# NUC1263AE register map
File version: 1.0
Registers are 32-bit, read-write, reset 0x0 unless marked. A register's access mark holds for its fields unless they carry their own. Offsets are from the block's base; [hi:lo] are bit positions; {n}, {i} and the like mark numbered series; 'fields as' and 'values as' point back to an identical list.

## I3CS0 — I3CS Register Map
Base 0x40070000
Same registers: I3CS1 0x40170000
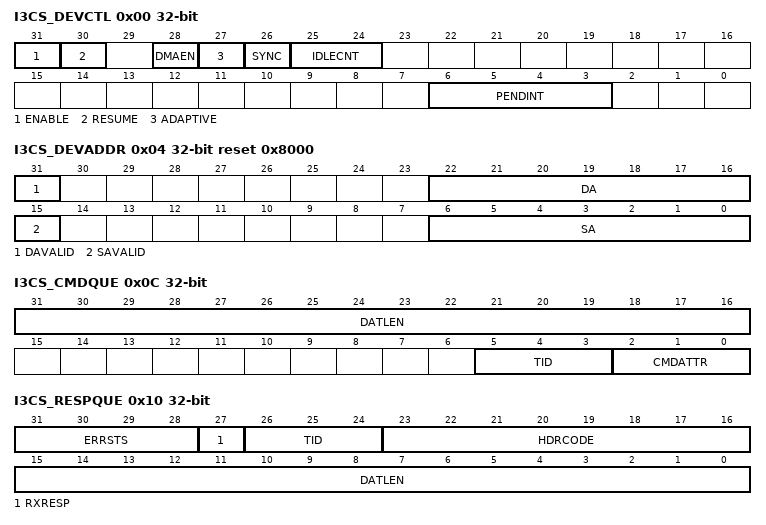
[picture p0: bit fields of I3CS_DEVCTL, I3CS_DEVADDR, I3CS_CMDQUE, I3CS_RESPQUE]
0x00 I3CS_DEVCTL — I3CS Device Control Register
  [31] ENABLE — Controls whether I3CS is enabled. This bit is used to disable or enable the I3CS cntroller. Note: User can read I3C_DEVCTL[26] SYNC bit to monitor enable/disable I3C is completion ot not.
    0=I3CS controller Disabled; 1=I3CS controller Enabled
  [30] RESUME — I3CS Resume Bit. This bit is used to resume the controller after it goes to the halt state. Note 1: This bit is cleared by writing 1 to it. Note 2: In the Slave mode of operation, the controller goes to the halt state due to following conditions: Any type of error in the transfer. MRL Register (I3CS_SLVMXLEN[31:16]) updated by the master through SETMRL CCC. Note 3: After the controller goes to the halt state, the application has to take necessary action to handle the error condition and then write 1'b1 to this bit to resume the controller. This bit is auto-cleared once the controller is ready to accept new transfers.RESUME cannot be auto cleared until GETSTATS CCC is received if Slave has Protocol Error.
    0=RESUME operation is completion; 1=RESUME operation is in progress
  [28] DMAEN — DMA Handshake Interface Enable
    0=The DMA handshake control has no significance; 1=Enables the DMA handshake control to interact with external DMA
  [27] ADAPTIVE — Adaptive Mode. Setting of this bit is NOT required to put the controller in Adaptive Mode. It is only used to enable some features of the Slave controller to adapt to Adaptive I2C/I3C mode of operation. This bit is cleared automatically if the controller determines the mode as I3C. (Effect on Hot- Join). If this bit is programmed to 1'b1, the controller initiates a Hot-Join request only after it has switched to I3C mode of operation. If this bit is not set, the controller initiates a Hot- Join without determining the bus mode assuming itself to be on i3c bus. This bit should be set only if the Slave application does not know to which bus the device is connected to.
    0=Adptive mode is Disabled; 1=Adptive mode is Enabled
  [26] SYNC ro — Enable I3C Controller SYNC Flag (Read Only)
    0=Enables the I3C controller is completed; 1=Enables the I3C controller is ongoing
  [25:24] IDLECNT — Idle Count Multiplier. After power-on reset, the Slave controller is enabled only after it sees both SDA and SCL lines idle for a specified time. This idle time is calculated by multiplying IDLECNT with Bus Avaliable Time.
    0=1 Idle Count; 1=2 Idle Counts; 2=4 Idle Counts; 3=8 Idle Counts
  [6:3] PENDINT — Pending Interrupt Status. This field is used for setting the interrupt number and is also reflected in I3CS_CCCDEVS[3:0] PENDINT.
0x04 I3CS_DEVADDR reset 0x8000 — I3CS Device Address Register
  [31] DAVALID — Dynamic Address Valid. In I3C Slave mode, the Controller sets this bit to 1 when Main Master assigns the Dynamic address during ENTDAA or SETDASA mechanism. Note: This bit can be auto cleared to 0 if RSTDAA CCC is received.
    0=Dynamic Address is invalid; 1=Dynamic Address is valid
  [22:16] DA ro — Device Dynamic Address (Read Only). This field is used to indicate the device Dynamic Address after slave completes the dynamic address assignment operation by ENTDAA, SETDASA or SETNEDA CCC.
  [15] SAVALID — Static Address Valid. This bit reflects whether the I2C static address is valid in I2C slave mode.
    0=Static Address is invalid; 1=Static Address is valid
  [6:0] SA — Device Static Address. The I2C static address is used to respond to SETDASA CCC Command to get the Dynamic Address or performs Legacy I2C Read/Write operation.
0x0C I3CS_CMDQUE wo — I3CS Command Queue Port Register
  [31:16] DATLEN — Data Length. This field is used to indicate the data length in bytes of the master read transfer.
  [5:3] TID — Transmit Transaction ID. This field is used as the identification tag for the command.
  [2:0] CMDATTR — Command Attribute. Defines the command attribute and its field format.
    0=Transmit Command without IBI
0x10 I3CS_RESPQUE ro — I3CS Response Queue Port Register
  [31:28] ERRSTS — Error Status
    0=No Error; 1=CRC error (master write in DDR mode); 2=Parity error (master write in both DDR and SDR mode); 3=Frame error (HDR mode master write); 6=Underflow/Overflow error; 10=Master early termination
  [27] RXRESP — Transaction Type. This field is used to identify the type of transaction.
    0=Transmit Response occurred; 1=Receive Response occurred
  [26:24] TID — Transmit Transaction ID. This field is used as the identification tag for the transmit command.
  [23:16] HDRCODE — HDR Command Code
    0=SDR Transfer
  [15:0] DATLEN — Data Length. Data Length in bytes of Master Write Transfer or the Remaining Length of Master Read Transfer (Master termination or Slave underrun).
0x14 I3CS_TXRXDAT — I3CS Transmit and Receive Data Port Register
  [31:0] DAT — Transmit and Receive Data Port. Transmit (Write) Operation: The Transmit Data port is mapped to the Tx-Data Buffer. The transmit data should always be packed as 4-byte aligned data words and written to the Transmit Data Port register. If the Command length is not aligned to 4-bytes, then the additional bytes are ignored. Receive (Read) Operation: The Receive Data port is mapped to the Rx-Data Buffer. The Receive data is always packed in 4-byte aligned data words and stored in the Rx-Data Buffer. If the command length is not aligned to the 4-bytes, then the additional data bytes have to be ignored.
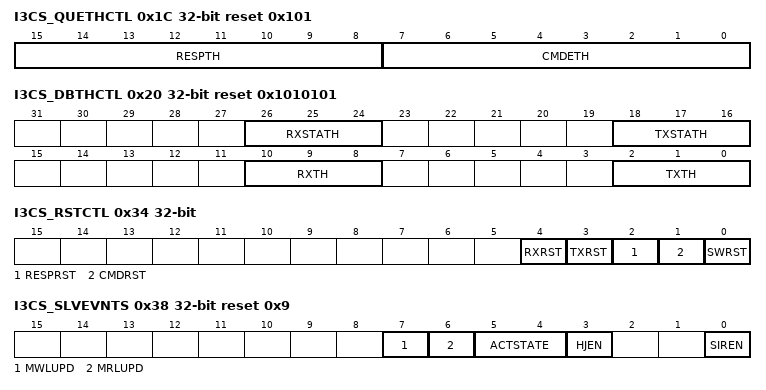
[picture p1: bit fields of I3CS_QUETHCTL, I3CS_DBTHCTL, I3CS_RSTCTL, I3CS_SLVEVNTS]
0x1C I3CS_QUETHCTL reset 0x101 — I3CS Queue Threshold Control Register
  [15:8] RESPTH — Response Buffer Threshold Value. Controls the number of entries (or greater) in the ResponseQueue that trigger the Response Queue Ready interrupt (RESPRDY). The valid range is 0 to 1. The software programs only valid values. A value of 0 sets the threshold for 1 entry, and a value of N sets the threshold for N+1 entries.
  [7:0] CMDETH — Command Buffer Empty Threshold Value. Controls the number of empty locations (or greater) in the Command Queue that trigger the Command Queue Ready interrupt (CMDRDY). The valid range is 0 to 3. The software programs only valid values. Value of N ranging from 1 to 3 sets the threshold to N empty locations and a value of 0 sets the threshold to indicate that the queue is completely empty.
0x20 I3CS_DBTHCTL reset 0x1010101 — I3CS Data Buffer Threshold Control Register
  [all] fields
    0=1; 1=4; 2=8; 3=16
  [26:24] RXSTATH — Receive Start Threshold Value. In the slave mode of operation the slave controller ACK's a write request from Master only if threshold number of empty locations(or more) are available in its receive buffer. The supported values for RXSTATH are:
  [18:16] TXSTATH — Transfer Start Threshold Value. In slave mode of operation the slave controller ACK's a read request from Master only if either one of the following conditions are met: 1. Data length (as specified in the command) number of locations are filled in the Transmit FIFO. 2. Threshold number of entries (or more) are available in the Transmit FIFO. The supported values for RXSTATH are:
  [10:8] RXTH — Receive Buffer Threshold Value. The supported values for RXTH are
  [2:0] TXTH — Transmit Buffer Threshold Value. The supported values for TXTH are
0x34 I3CS_RSTCTL — I3CS Reset Control Register
  [4] RXRST — Receive Buffer Software Reset. Write 1'b1 to this bit to exercise Receive Buffer reset. This bit is cleared automatically once the Receive buffer reset is completed.
  [3] TXRST — Transmit Buffer Software Reset. Write 1'b1 to this bit to exercise Transmit Buffer reset. This bit is cleared automatically once the Transmit Buffer reset is completed.
  [2] RESPRST — Response Queue Software Reset. Write 1'b1 to this bit to exercise Response Queue reset. This bit is cleared automatically once the Response Queue reset is completed.
  [1] CMDRST — Command Queue Software Reset. Write 1'b1 to this bit to exercise Command Queue reset. This bit is cleared automatically once the Command Queue reset is completed.
  [0] SWRST — Core Software Reset. Write 1'b1 to this bit to exercise software reset. This resets all Buffers - Receive, Transmit and Queues - Command, and Response. This bit is cleared automatically once the core reset is completed.
0x38 I3CS_SLVEVNTS reset 0x9 — I3CS Slave Event Status Register
  [7] MWLUPD — MWL Updated Status. This bit indicates a SETMWL CCC is received by the slave. The updated MWL value can be read from I3CS_SLVMXLEN register. Note: This bit is cleared by writing 1 to it.
  [6] MRLUPD — MRL Updated Status. This bit indicates a SETMRL CCC is received by the slave. The updated MRL value can be read from I3CS_SLVMXLEN register. Note: This bit is cleared by writing 1 to it.
  [5:4] ACTSTATE ro — Activity State Status (Read Only). This bit reflects the Activity State of slave set by the Master. ENTAS0 - 00. ENTAS1 - 01. ENTAS2 - 10. ENTAS3 - 11
  [3] HJEN ro — Hot-Join Interrupt Enable Bit (Read Only). This bit reflects whether the Hot-Join Request Interrupts are allowed on the I3C bus or not. The Slave application can choose to Disable HJ Capability of the SLave Controller (if selected) by setting this field to 0 before 'Enabling' the Controller. When done so, the Slave does not initiate Hot Join and takes part in Address Assignment without initiating Hot Join. If this field is NOT set to 0 by slave application, it can be set or cleared by the I3C Master through ENEC or DISEC CCCs. Once Disabled by software, CCCs do not have any effect on this field.
  [0] SIREN ro — Slave Interrupt Request Enable Bit (Read Only). In Slave mode of operation, this bit reflects whether the controller can initiate the SIR on the I3C bus or not. Usually, this bit is set or cleared by the I3C Master through ENEC or DISEC CCC.
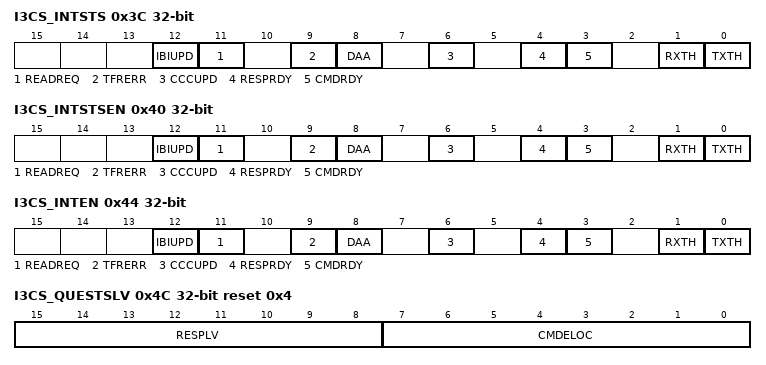
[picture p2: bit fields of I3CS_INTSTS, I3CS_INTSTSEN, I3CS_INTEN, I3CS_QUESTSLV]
0x3C I3CS_INTSTS — I3CS Interrupt Status Register
  [12] IBIUPD — IBI Status Updated. It indicates that the IBI request initiated through SIR request register is addressed and status is updated. Note: This bit is cleared by writing 1 to it.
  [11] READREQ — Read Request Received. Read Request received from the current master when CMDQ is empty. Note: This bit is cleared by writing 1 to it.
  [9] TFRERR — Transfer Error Status. This interrupt is generated if any error occurs during transfer. The error type is specified in the error status field of resopnse queue. Note: This bit is cleared by writing 1 to it.
  [8] DAA — Dynamic Address Assigned Status. This interrupt is generated if the device's Dynamic Address is assigned through SETDASA or ENTDAA CCC. Note: This bit is cleared by writing 1 to it.
  [6] CCCUPD — CCC Table Updated Status. This interrupt is generated if any of the CCC registers are updated by I3C Master through CCC commands. Note: This bit is cleared by writing 1 to it.
  [4] RESPRDY ro — Response Queue Ready Status (Read Only). This interrupt is generated when number of entries in response queue is greater than or equal to threshold valuespecified by RESPTH field in QUETHCTL register. This interrupt is cleared automatically when number of entries in response buffer is less than threshold value specified.
  [3] CMDRDY ro — Command Queue Ready Status (Read Only). This interrupt is generated when number of empty locations in command queue is greater than or equal to threshold value specified by CMDETH field in QUETHCTL register. This interrupt is cleared automatically when number of empty locations in command buffer is less than threshold value specified.
  [1] RXTH ro — Receive Buffer Threshold Status (Read Only). This interrupt is generated when number of entries in receive buffer is greater than or equal to threshold value specified by RXTH field in DBTHCTL register. This interrupt is cleared automatically when number of entries in receive buffer is less than threshold value specified.
  [0] TXTH ro — Transmit Buffer Threshold Status (Read Only). This interrupt is generated when the number of empty locations in transmit buffer is greater than or equal to threshold value specified by TXTH field in DBTHCTL register. This interrupt is cleared automatically when number of empty locations in transmit buffer is less than threshold value specified.
0x40 I3CS_INTSTSEN — I3CS Interrupt Status Enable Register
  [12] IBIUPD — IBI Updated Status Enable Bit
    0=IBI interrupt status Disabled; 1=IBI interrupt status Enabled
  [11] READREQ — Read Request Received Status Enable
    0=Read request received interrupt status Disabled; 1=Read request received interrupt status Enabled
  [9] TFRERR — Transfer Error Status Enable
    0=Transfer error interrupt status Disabled; 1=Transfer error interrupt status Enabled
  [8] DAA — Dynamic Address Assigned Status Enable
    0=DAA interrupt status Disabled; 1=DAA interrupt status Enabled
  [6] CCCUPD — CCC Table Updated Status Enable Bit
    0=CCC updated interrupt status Disabled; 1=CCC updated interrupt status Enabled
  [4] RESPRDY — Response Queue Ready Status Enable
    0=Response queue ready interrupt status Disabled; 1=Response queue ready interrupt status Enabled
  [3] CMDRDY — Command Queue Ready Status Enable
    0=Command queue ready interrupt status Disabled; 1=Command queue ready interrupt status Enabled
  [1] RXTH — Receive Buffer Threshold Status Enable
    0=RX buffer threshold interrupt status Disabled; 1=RX buffer threshold interrupt status Enabled
  [0] TXTH — Transmit Buffer Threshold Status Enable
    0=TX buffer threshold interrupt status Disabled; 1=TX buffer threshold interrupt status Enabled
0x44 I3CS_INTEN — I3CS Interrupt Signal Enable Register
  [12] IBIUPD — IBI Updated Signal Enable
    0=IBI interrupt Disabled; 1=IBI interrupt Enabled
  [11] READREQ — Read Request Received Signal Enable
    0=Read request received interrupt Disabled; 1=Read request received interrupt Enabled
  [9] TFRERR — Transfer Error Signal Enable
    0=Transfer error interrupt Disabled; 1=Transfer error interrupt Enabled
  [8] DAA — Dynamic Address Assigned Signal Enable
    0=DAA interrupt Disabled; 1=DAA interrupt Enabled
  [6] CCCUPD — CCC Table Updated Signal Enable
    values as I3CS_INTSTSEN.CCCUPD
  [4] RESPRDY — Response Queue Ready Signal Enable
    0=Response queue ready interrupt Disabled; 1=Response queue ready interrupt Enabled
  [3] CMDRDY — Command Queue Ready Signal Enable
    0=Command queue ready interrupt Disabled; 1=Command queue ready interrupt Enabled
  [1] RXTH — Receive Buffer Threshold Signal Enable
    0=RX buffer threshold interrupt Disabled; 1=RX buffer threshold interrupt Enabled
  [0] TXTH — Transmit Buffer Threshold Signal Enable
    0=TX buffer threshold interrupt Disabled; 1=TX buffer threshold interrupt Enabled
0x4C I3CS_QUESTSLV ro reset 0x4 — I3CS Queue Status Level Register
  [15:8] RESPLV — Response Buffer Level Value. Contains the number of valid data entries in the response Buffer.
  [7:0] CMDELOC — Command Queue Empty Locations. Contains the number of empty locations in the command Buffer.
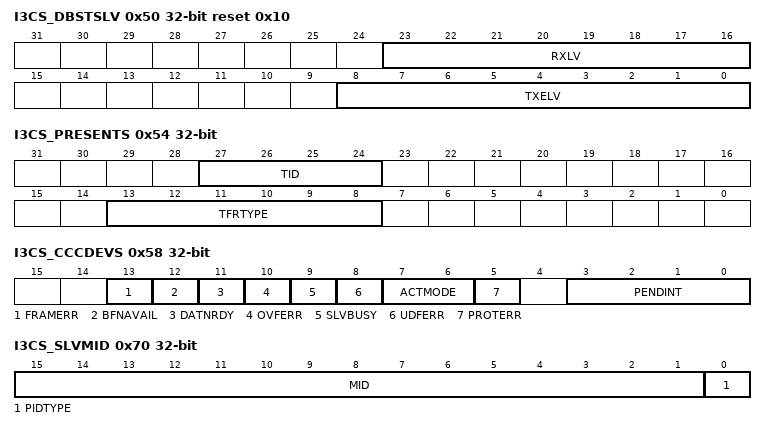
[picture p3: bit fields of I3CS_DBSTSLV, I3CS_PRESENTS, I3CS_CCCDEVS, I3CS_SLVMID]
0x50 I3CS_DBSTSLV ro reset 0x10 — I3CS Data Buffer Status Level Register
  [23:16] RXLV — Receive Buffer Level Value. Contains the number of valid data entries in the receive Buffer.
  [8:0] TXELV — Transmit Buffer Empty Level Value. Contains the number of empty locations in the transmit Buffer.
0x54 I3CS_PRESENTS ro — I3CS Present State Register
  [27:24] TID — Transmit Transaction ID. This field reflects the Transaction ID of the current executing command.
  [13:8] TFRTYPE — Transfer Type Status in Slave Mode
    0=IDLE (Controller is in Idle state); 1=Hot-Join transfer state; 2=IBI transfer state; 3=Master write transfer ongoing; 4=Read data prefetch state; 5=Master read transfer ongoing; 6=Slave controller in Halt State waiting for resume from application
0x58 I3CS_CCCDEVS ro — I3CS Device Operating Status Register
  [13] FRAMERR — Frame Error. This bit is set when private write request from Master has frame error in HDR-DDR mode. This is cleared only after Master reads the device status through GETSTATUS CCC.
    0=Frame error event did not occur; 1=Frame error event occurred
  [12] BFNAVAIL — Buffer Not Available. This bit is set when private write request from Master is NACKED because of RX buffer not having RXTH number of empty locations or Response buffer is full. In SDR mode of operation this is cleared when the Master issues GETSTATUS CCC or upon space becoming available in the buffer and the successful completion of the next write transfer. In HDR mode of operation it is cleared only when Master issues GETSTATUS CCC.
    0=Buffer not available event did not occur; 1=Buffer not available event occurred
  [11] DATNRDY — Data Not Ready. This bit is set when private read request from Master is NACKED because of any of the following conditions: Command FIFO Empty. Transmit FIFO threshold is not met. Response FIFO Full. This is cleared when the Master issues GETSTATUS CCC or upon successful completion of the subsequent read transfer.
    0=Data not ready event did not occur; 1=Data not ready event occurred
  [10] OVFERR — Overflow Error. This bit is set while overflow error condition detected during master write transfer. This is cleared only after master reads the Device Status through GETSTATUS CCC.
    0=Overflow error event did not occur; 1=Overflow error event occurred
  [9] SLVBUSY — Slave Busy. This bit is set if any change is made by the current master in to MRL register or occurance of any error. It is cleared after slave application resumes the slave operation by writing 1'b1 in RESUME field of I3CS_DEVCTL.
    0=Slave controller is not at busy state; 1=Slave controller is at busy state
  [8] UDFERR — Underflow Error. This bit is set if slave controller terminates a read transfer because of unavailability of data in the transmit buffer. This is cleared only after master reads the Device Status through GETSTATUS CCC.
    0=Underflow error event did not occur; 1=Underflow error event occurred
  [7:6] ACTMODE — Activity Mode. This field indicates current Activity Mode is fixed at 0 in NUC1263.
  [5] PROTERR — Protocol Error. This bit is set when the slave controller encouters a Parity/CRC error during write data transfer.
    0=Protocol error event did not occur; 1=Protocol error event occurred
  [3:0] PENDINT — Pending Interrupt. This field reflects the value in I3CS_DEVCTL[6:3].
0x70 I3CS_SLVMID — I3CS MIPI Manufacturer ID Register
  [15:1] MID — Specifies the MIPI Manufacturer ID. The value of this field is indicating the MIPI Manufacturer ID, PID[47:33].
  [0] PIDTYPE — Specifies the Provisional ID Type Selector. The value of this field is indicating the Provisional ID Type, PID[32].
    0=Vendor Fixed Value; 1=Random Value
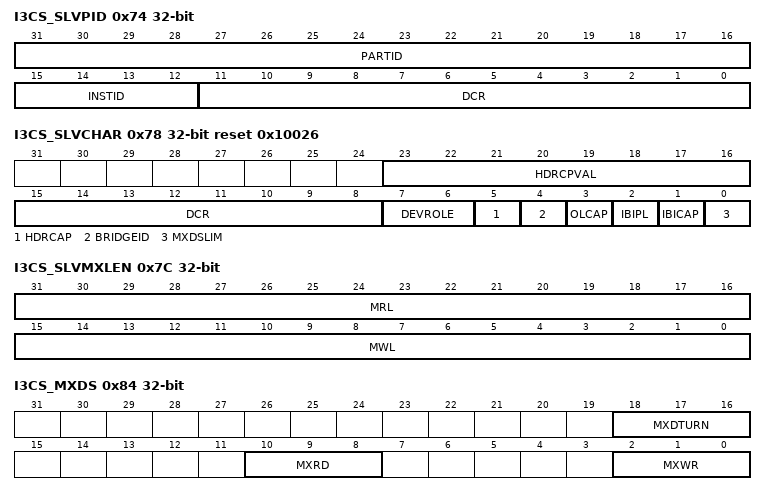
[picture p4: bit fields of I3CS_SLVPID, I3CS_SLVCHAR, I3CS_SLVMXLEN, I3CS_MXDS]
0x74 I3CS_SLVPID — I3CS Normal Provisional ID Register
  [31:16] PARTID — Specifies the Part ID of I3C device. The value of this field is indicating the Part ID, PID[31:16].
  [15:12] INSTID — This Field is used to Program the Instance ID of the Slave. The value of this field is indicating the instance ID, PID[15:12].
  [11:0] DCR — Specifies the Additional 12-bit ID of I3C Device. The value of this field is indicating the Additional 12-bit ID, PID[11:0].
0x78 I3CS_SLVCHAR reset 0x10026 — I3CS Slave Characteristic Register
  [23:16] HDRCPVAL ro — I3C Device HDR Capability Register Value (Read Only). The value of this field is fixed at 1, indicating HDR-DDR.
  [15:8] DCR — I3C Device Characteristic Value. The value of this field can be set as Device Characteristic Value.
  [7:6] DEVROLE ro — Device Role Field in Bus Characteristic Register (Read Only). The value of this field is fixed at 0 (BCR[7:6]), indicating I3C Slave.
  [5] HDRCAP — SDR Only or SDR and HDR Capable field in Bus Characteristic Register. The value of this field is indicating the BCR[5] value.
    0=SDR only; 1=HDR capable
  [4] BRIDGEID ro — Bridge Identifier Field in Bus Characteristic Register (Read Only). The value of this field is fixed at 0 (BCR[4]), indicating Not a bridge device.
  [3] OLCAP ro — Offline Capable Field in Bus Characteristic Register (Read Only). The value of this field is fixed at 0 (BCR[3]), indicating Slave will always respond to I3C bus commands.
  [2] IBIPL ro — IBI Payload Field in Bus Characteristic Register (Read Only). The value of this field is fixed at 1 (BCR[2]), indicating Support IBI payload.
  [1] IBICAP ro — IBI Request Capable Field in Bus Characteristic Register (Read Only). The value of this field is fixed at 1 (BCR[1]), indicating Support IBI generation.
  [0] MXDSLIM — Max Data Speed Limitation field in Bus Characteristic Register. The value of this field is indicating the BCR[0] value.
    0=No limitation; 1=Limitation
0x7C I3CS_SLVMXLEN ro — I3CS Maximum Write/Read Length Register
  [31:16] MRL — I3C Device Max Read Length. This field will be updated if SETMRL CCC is received.
  [15:0] MWL — I3C Device Max Write Length. This field will be updated if SETMWL CCC is received.
0x80 I3CS_MXRDTURN ro — I3CS Maximum Read Turnaround Time Register
  [23:0] MXRDTURN — Specifies the Maximum Read Tturnaround Time (Read Only). The 3rd byte which returned in the GETMXDS CCC (in microseconds (us))
0x84 I3CS_MXDS — I3CS Maximum Data Speed Register
  [18:16] MXDTURN — Specifies the Clock to Data Turnaround Time
    {v}={v+8} ns (v=0..4)
  [10:8] MXRD — Specifies the Maximum Sustained Data Rate for Non-CCC Messages Sent by Slave Device to Master Device. The 2nd byte which returned in the GETMXDS CCC.
    0=12.5 MHz; 1=8 MHz; 2=6 MHz; 3=4 MHz; 4=2 MHz
  [2:0] MXWR — Specifies the Maximum Sustained Data Rate for Non-CCC Messages Sent by Master Device to Slave device. The 1st byte which returned in the GETMXDS CCC.
    0=12.5 MHz; 1=8 MHz; 2=6 MHz; 3=4 MHz; 4=2 MHz
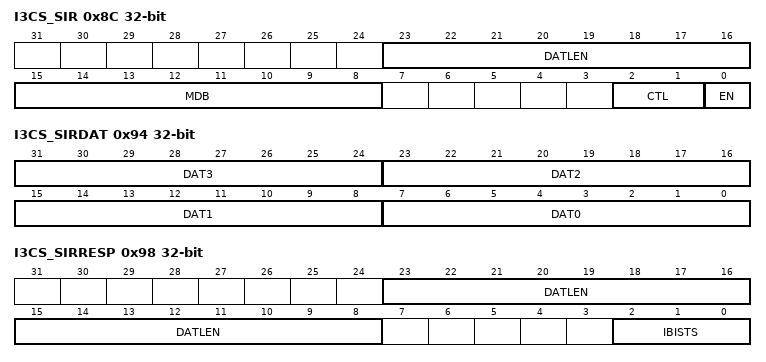
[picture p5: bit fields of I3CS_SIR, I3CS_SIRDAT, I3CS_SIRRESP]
0x8C I3CS_SIR — I3CS Slave Interrupt Request Register
  [23:16] DATLEN — Slave Interrupt Request Data Length. This field should be programmed by the slave application to give the data length for the payload data other than the MDB byte. This field is only applicable when BCR[2] is set indicating that SIR supports payload data.
  [15:8] MDB — Mandatory Data Byte. This field gives the mandatory data byte which is required to be transmitted after the Master ACK the slave address during SIR transfer. This field is only applicable when I3C_SLVCHAR[2] IBIPL (BCR[2]) is set indicating that SIR supports payload data.
  [2:1] CTL — Slave Interrupt Request Control
    0=Indicates source of SIR data to be from the registers
  [0] EN — Slave Interrupt Request. When set, the slave controller attempts to issue the SIR on the I3C bus. Once issued and when the current master accepts (ACK) or if the controller is unable to issue the SIR, then the controller clears this bit automatically and updates the I3CS_SIRRESP[2:0] IBISTS. If the NACK response is received for the SIR, the controller reattempts the SIR upon detecting the next START condition from the master or after the Bus Available Time. Once set, the application cannot clear this bit.
0x94 I3CS_SIRDAT — I3CS Slave Interrupt Request Data Register
  [31:24] DAT3 — SIR Data Byte 3. This register SIRDAT containing four bytes of SIR Data will be in effect only when CTL field in I3CS_SIR register is programmed to 00 provided the data length is up to 4. This field holds the fourth byte of SIR DATA that will be passed after the MDB when SIR is initiated by the application on writing into EN bit in I3CS_SIR register.
  [23:16] DAT2 — SIR Data Byte 2. This register SIRDAT containing four bytes of SIR Data will be in effect only when CTL field in I3CS_SIR register is programmed to 00 provided the data length is up to 3. This field holds the third byte of SIR DATA that will be passed after the MDB when SIR is initiated by the application on writing into EN bit in I3CS_SIR register.
  [15:8] DAT1 — SIR Data Byte 1. This register SIRDAT containing four bytes of SIR Data will be in effect only when CTL field in I3CS_SIR register is register programmed to 00 provided the data length is up to 2. This field holds the second byte of SIR DATA that will be passed after the MDB when SIR is initiated by the application on writing into EN bit in I3CS_SIR register.
  [7:0] DAT0 — SIR Data Byte 0. This register SIRDAT containing four bytes of SIR Data will be in effect only when CTL field in I3CS_SIR register is programmed to 00 provided the data length is up to 1. This field holds the first byte of SIR DATA that will be passed after the MDB when SIR is initiated by the application on writing into EN bit in I3CS_SIR register.
0x98 I3CS_SIRRESP — I3CS Slave Interrupt Request Response Register
  [23:8] DATLEN — Data Length for SIR Response. The value in this filed will indicate the number of bytes remaining that was not transmitted because of Master early terminating the SIR transfer. In case the IBI is not attempted the number for bytes returned will be same as that programmed for IBI payload
  [2:0] IBISTS — IBI Completion Status. This field is common for SIR. The controller does not attempt to issue the IBI and generates the IBI Completion Status as 3'b011 if one of the following condition is true. Master has not assigned the Dynamic Address. Master has cleared the assigned Dynamic Address (through RSTDAA CCC). Master has disabled the IBI event (through DISEC CCC). The controller has switched the role to Master (applicable only for secondary master configuration). DATLEN doesn't match with I3CS_SIR[23:16].
    1=IBI accepted by the Master (ACK response received); 2=Master Early Terminate (only for SIR with Data); 3=IBI Not Attempted
0xD4 I3CS_BUSFAT reset 0x200000 — I3CS Bus Free and Available Timing Register
  [31:16] AVAILTC — Bus Avaliable Time Count Value. This register field is used only in Slave mode of operation Bus Available Count Value . This field is used by the Slaveto initiate an IBI after STOP condition. Note: IBI event can be generated after bus available time expires.
0xD8 I3CS_BUSIDLET reset 0x20 — I3CS Bus Idle Timing Register
  [19:0] IDLETC — Bus Idle Time Count Value. This field is used by the controller in Slave mode to initiate Hot-Join request if the dynamic address is not valid. Note: Hot-Join event can be generated after bus idle time expires.
